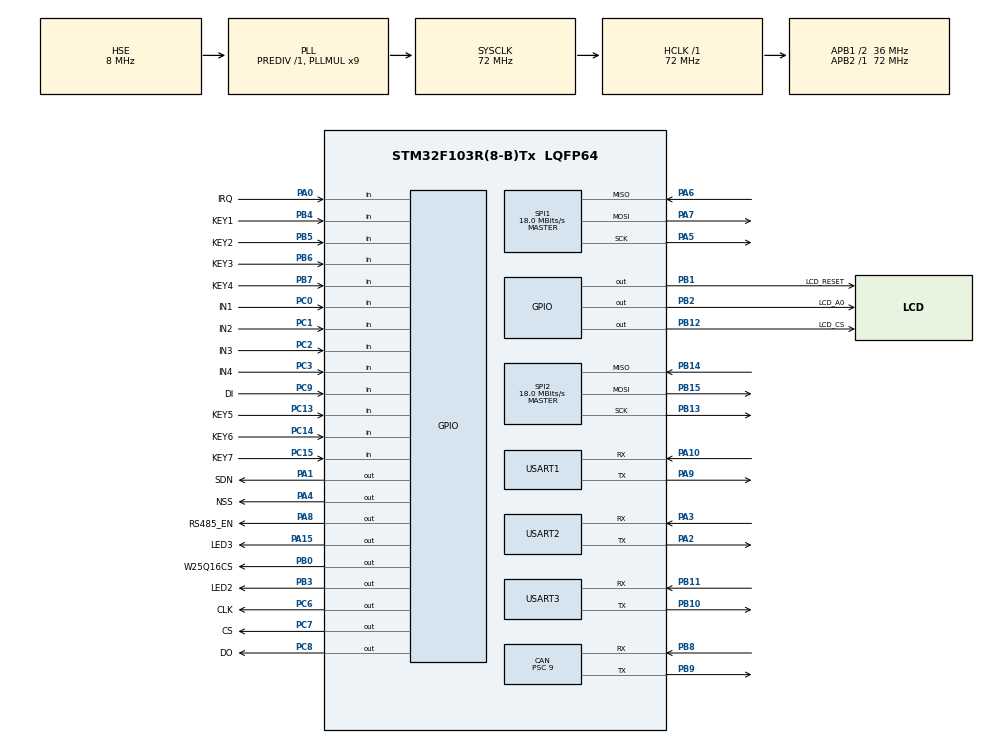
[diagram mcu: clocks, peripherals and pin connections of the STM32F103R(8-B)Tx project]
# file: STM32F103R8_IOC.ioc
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CAN.BS1=CAN_BS1_3TQ
CAN.BS2=CAN_BS2_4TQ
CAN.CalculateTimeBit=2000
CAN.CalculateTimeQuantum=250.0
CAN.NART=ENABLE
CAN.Prescaler=9
Dma.Request0=USART1_RX
Dma.Request1=USART1_TX
Dma.Request2=USART2_RX
Dma.Request3=USART2_TX
Dma.Request4=USART3_RX
Dma.Request5=USART3_TX
Dma.USART1_RX.0.Direction=DMA_PERIPH_TO_MEMORY
Dma.USART1_RX.0.Instance=DMA1_Channel5
Dma.USART1_RX.0.MemDataAlignment=DMA_MDATAALIGN_BYTE
Dma.USART1_RX.0.MemInc=DMA_MINC_ENABLE
Dma.USART1_RX.0.Mode=DMA_CIRCULAR
Dma.USART1_RX.0.PeriphDataAlignment=DMA_PDATAALIGN_BYTE
Dma.USART1_RX.0.PeriphInc=DMA_PINC_DISABLE
Dma.USART1_RX.0.Priority=DMA_PRIORITY_LOW
Dma.USART1_TX.1.Direction=DMA_MEMORY_TO_PERIPH
Dma.USART1_TX.1.Instance=DMA1_Channel4
Dma.USART1_TX.1.MemDataAlignment=DMA_MDATAALIGN_BYTE
Dma.USART1_TX.1.MemInc=DMA_MINC_ENABLE
Dma.USART1_TX.1.Mode=DMA_NORMAL
Dma.USART1_TX.1.PeriphDataAlignment=DMA_PDATAALIGN_BYTE
Dma.USART1_TX.1.PeriphInc=DMA_PINC_DISABLE
Dma.USART1_TX.1.Priority=DMA_PRIORITY_LOW
Dma.USART2_RX.2.Direction=DMA_PERIPH_TO_MEMORY
Dma.USART2_RX.2.Instance=DMA1_Channel6
Dma.USART2_RX.2.MemDataAlignment=DMA_MDATAALIGN_BYTE
Dma.USART2_RX.2.MemInc=DMA_MINC_ENABLE
Dma.USART2_RX.2.Mode=DMA_CIRCULAR
Dma.USART2_RX.2.PeriphDataAlignment=DMA_PDATAALIGN_BYTE
Dma.USART2_RX.2.PeriphInc=DMA_PINC_DISABLE
Dma.USART2_RX.2.Priority=DMA_PRIORITY_LOW
Dma.USART2_TX.3.Direction=DMA_MEMORY_TO_PERIPH
Dma.USART2_TX.3.Instance=DMA1_Channel7
Dma.USART2_TX.3.MemDataAlignment=DMA_MDATAALIGN_BYTE
Dma.USART2_TX.3.MemInc=DMA_MINC_ENABLE
Dma.USART2_TX.3.Mode=DMA_NORMAL
Dma.USART2_TX.3.PeriphDataAlignment=DMA_PDATAALIGN_BYTE
Dma.USART2_TX.3.PeriphInc=DMA_PINC_DISABLE
Dma.USART2_TX.3.Priority=DMA_PRIORITY_LOW
Dma.USART3_RX.4.Direction=DMA_PERIPH_TO_MEMORY
Dma.USART3_RX.4.Instance=DMA1_Channel3
Dma.USART3_RX.4.MemDataAlignment=DMA_MDATAALIGN_BYTE
Dma.USART3_RX.4.MemInc=DMA_MINC_ENABLE
Dma.USART3_RX.4.Mode=DMA_CIRCULAR
Dma.USART3_RX.4.PeriphDataAlignment=DMA_PDATAALIGN_BYTE
Dma.USART3_RX.4.PeriphInc=DMA_PINC_DISABLE
Dma.USART3_RX.4.Priority=DMA_PRIORITY_LOW
Dma.USART3_TX.5.Direction=DMA_MEMORY_TO_PERIPH
Dma.USART3_TX.5.Instance=DMA1_Channel2
Dma.USART3_TX.5.MemDataAlignment=DMA_MDATAALIGN_BYTE
Dma.USART3_TX.5.MemInc=DMA_MINC_ENABLE
Dma.USART3_TX.5.Mode=DMA_NORMAL
Dma.USART3_TX.5.PeriphDataAlignment=DMA_PDATAALIGN_BYTE
Dma.USART3_TX.5.PeriphInc=DMA_PINC_DISABLE
Dma.USART3_TX.5.Priority=DMA_PRIORITY_LOW
Mcu.Family=STM32F1
Mcu.Name=STM32F103R(8-B)Tx
Mcu.Package=LQFP64
NVIC.DMA1_Channel2_IRQn=true\:0\:0\:false\:false\:true\:false\:true
NVIC.DMA1_Channel3_IRQn=true\:0\:0\:false\:false\:true\:false\:true
NVIC.DMA1_Channel4_IRQn=true\:0\:0\:false\:false\:true\:false\:true
NVIC.DMA1_Channel5_IRQn=true\:0\:0\:false\:false\:true\:false\:true
NVIC.DMA1_Channel6_IRQn=true\:0\:0\:false\:false\:true\:false\:true
NVIC.DMA1_Channel7_IRQn=true\:0\:0\:false\:false\:true\:false\:true
NVIC.PriorityGroup=NVIC_PRIORITYGROUP_4
NVIC.TIM2_IRQn=true\:0\:0\:false\:false\:true\:true\:true
NVIC.TIM3_IRQn=true\:0\:0\:false\:false\:true\:true\:true
NVIC.USART1_IRQn=true\:0\:0\:false\:false\:true\:true\:true
NVIC.USART2_IRQn=true\:0\:0\:false\:false\:true\:true\:true
NVIC.USART3_IRQn=true\:0\:0\:false\:false\:true\:true\:true
NVIC.USB_LP_CAN1_RX0_IRQn=true\:0\:0\:false\:false\:true\:true\:true
PA0-WKUP.GPIO_Label=IRQ
PA0-WKUP.GPIO_PuPd=GPIO_PULLUP
PA0-WKUP.Signal=GPIO_Input
PA1.GPIO_Label=SDN
PA1.GPIO_PuPd=GPIO_PULLUP
PA1.Signal=GPIO_Output
PA10.Mode=Asynchronous
PA10.Signal=USART1_RX
PA13.Mode=Serial_Wire
PA13.Signal=SYS_JTMS-SWDIO
PA14.Mode=Serial_Wire
PA14.Signal=SYS_JTCK-SWCLK
PA15.GPIO_Label=LED3
PA15.GPIO_PuPd=GPIO_PULLUP
PA15.PinState=GPIO_PIN_SET
PA15.Signal=GPIO_Output
PA2.Mode=Asynchronous
PA2.Signal=USART2_TX
PA3.Mode=Asynchronous
PA3.Signal=USART2_RX
PA4.GPIO_Label=NSS
PA4.Signal=GPIO_Output
PA5.Mode=Full_Duplex_Master
PA5.Signal=SPI1_SCK
PA6.Mode=Full_Duplex_Master
PA6.Signal=SPI1_MISO
PA7.Mode=Full_Duplex_Master
PA7.Signal=SPI1_MOSI
PA8.GPIO_Label=RS485_EN
PA8.Signal=GPIO_Output
PA9.Mode=Asynchronous
PA9.Signal=USART1_TX
PB0.GPIO_Label=W25Q16CS
PB0.GPIO_PuPd=GPIO_PULLUP
PB0.Signal=GPIO_Output
PB1.GPIO_Label=LCD_RESET
PB1.GPIO_PuPd=GPIO_PULLUP
PB1.Signal=GPIO_Output
PB10.Mode=Asynchronous
PB10.Signal=USART3_TX
PB11.Mode=Asynchronous
PB11.Signal=USART3_RX
PB12.GPIO_Label=LCD_CS
PB12.GPIO_PuPd=GPIO_PULLUP
PB12.Signal=GPIO_Output
PB13.Mode=Full_Duplex_Master
PB13.Signal=SPI2_SCK
PB14.Mode=Full_Duplex_Master
PB14.Signal=SPI2_MISO
PB15.Mode=Full_Duplex_Master
PB15.Signal=SPI2_MOSI
PB2.GPIO_Label=LCD_A0
PB2.GPIO_PuPd=GPIO_PULLUP
PB2.Signal=GPIO_Output
PB3.GPIO_Label=LED2
PB3.GPIO_PuPd=GPIO_PULLUP
PB3.Signal=GPIO_Output
PB4.GPIO_Label=KEY1
PB4.GPIO_PuPd=GPIO_PULLUP
PB4.Signal=GPIO_Input
PB5.GPIO_Label=KEY2
PB5.GPIO_PuPd=GPIO_PULLUP
PB5.Signal=GPIO_Input
PB6.GPIO_Label=KEY3
PB6.GPIO_PuPd=GPIO_PULLUP
PB6.Signal=GPIO_Input
PB7.GPIO_Label=KEY4
PB7.GPIO_PuPd=GPIO_PULLUP
PB7.Signal=GPIO_Input
PB8.Mode=Master
PB8.Signal=CAN_RX
PB9.Mode=Master
PB9.Signal=CAN_TX
PC0.GPIO_Label=IN1
PC0.Signal=GPIO_Input
PC1.GPIO_Label=IN2
PC1.Signal=GPIO_Input
PC13-TAMPER-RTC.GPIO_Label=KEY5
PC13-TAMPER-RTC.GPIO_PuPd=GPIO_PULLUP
PC13-TAMPER-RTC.Signal=GPIO_Input
PC14-OSC32_IN.GPIO_Label=KEY6
PC14-OSC32_IN.GPIO_PuPd=GPIO_PULLUP
PC14-OSC32_IN.Signal=GPIO_Input
PC15-OSC32_OUT.GPIO_Label=KEY7
PC15-OSC32_OUT.GPIO_PuPd=GPIO_PULLUP
PC15-OSC32_OUT.Signal=GPIO_Input
PC2.GPIO_Label=IN3
PC2.Signal=GPIO_Input
PC3.GPIO_Label=IN4
PC3.Signal=GPIO_Input
PC6.GPIO_Label=CLK
PC6.PinState=GPIO_PIN_SET
PC6.Signal=GPIO_Output
PC7.GPIO_Label=CS
PC7.PinState=GPIO_PIN_SET
PC7.Signal=GPIO_Output
PC8.GPIO_Label=DO
PC8.Signal=GPIO_Output
PC9.GPIO_Label=DI
PC9.Signal=GPIO_Input
PD0-OSC_IN.Mode=HSE-External-Oscillator
PD0-OSC_IN.Signal=RCC_OSC_IN
PD1-OSC_OUT.Mode=HSE-External-Oscillator
PD1-OSC_OUT.Signal=RCC_OSC_OUT
ProjectManager.HeapSize=0x200
ProjectManager.StackSize=0x400
ProjectManager.TargetToolchain=MDK-ARM V5.27
RCC.AHBFreq_Value=72000000
RCC.APB1CLKDivider=RCC_HCLK_DIV2
RCC.APB1Freq_Value=36000000
RCC.APB1TimFreq_Value=72000000
RCC.APB2Freq_Value=72000000
RCC.APB2TimFreq_Value=72000000
RCC.HCLKFreq_Value=72000000
RCC.PLLMUL=RCC_PLL_MUL9
RCC.PLLSourceVirtual=RCC_PLLSOURCE_HSE
RCC.SYSCLKFreq_VALUE=72000000
RCC.SYSCLKSource=RCC_SYSCLKSOURCE_PLLCLK
RCC.USBFreq_Value=72000000
SPI1.BaudRatePrescaler=SPI_BAUDRATEPRESCALER_4
SPI1.CalculateBaudRate=18.0 MBits/s
SPI1.Direction=SPI_DIRECTION_2LINES
SPI1.Mode=SPI_MODE_MASTER
SPI1.VirtualType=VM_MASTER
SPI2.CalculateBaudRate=18.0 MBits/s
SPI2.Direction=SPI_DIRECTION_2LINES
SPI2.Mode=SPI_MODE_MASTER
SPI2.VirtualType=VM_MASTER
TIM2.Period=999
TIM2.Prescaler=71
TIM3.Period=999
TIM3.Prescaler=71
USART1.VirtualMode=VM_ASYNC
USART2.VirtualMode=VM_ASYNC
USART3.VirtualMode=VM_ASYNC
VP_TIM2_VS_ClockSourceINT.Mode=Internal
VP_TIM3_VS_ClockSourceINT.Mode=Internal
board=custom

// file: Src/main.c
/* USER CODE BEGIN Header */
/**
  ******************************************************************************
  * @file           : main.c
  * @brief          : Main program body
  ******************************************************************************
  * @attention
  *
  * <h2><center>&copy; Copyright (c) 2020 STMicroelectronics.
  * All rights reserved.</center></h2>
  *
  * This software component is licensed by ST under BSD 3-Clause license,
  * the "License"; You may not use this file except in compliance with the
  * License. You may obtain a copy of the License at:
  *                        opensource.org/licenses/BSD-3-Clause
  *
  ******************************************************************************
  */
/* USER CODE END Header */

#include "main.h"
#include "can.h"
#include "dma.h"
#include "spi.h"
#include "tim.h"
#include "usart.h"
#include "gpio.h"

/* USER CODE BEGIN Includes */
#include "app.h"
/* USER CODE END Includes */

void SystemClock_Config(void);

int main(void)
{

  /* MCU Configuration--------------------------------------------------------*/

  /* Reset of all peripherals, Initializes the Flash interface and the Systick. */
  HAL_Init();

  /* Configure the system clock */
  SystemClock_Config();

  /* Initialize all configured peripherals */
  MX_GPIO_Init();
  MX_DMA_Init();
  MX_CAN_Init();
  MX_SPI1_Init();
  MX_SPI2_Init();
  MX_TIM2_Init();
  MX_TIM3_Init();
  MX_USART1_UART_Init();
  MX_USART2_UART_Init();
  MX_USART3_UART_Init();

  /* Infinite loop */
  /* USER CODE BEGIN WHILE */
  while (1)
  {
	  ApplicationProgram_main();
    /* USER CODE END WHILE */

  }
}

void SystemClock_Config(void)
{
  RCC_OscInitTypeDef RCC_OscInitStruct = {0};
  RCC_ClkInitTypeDef RCC_ClkInitStruct = {0};

  /** Initializes the CPU, AHB and APB busses clocks
  */
  RCC_OscInitStruct.OscillatorType = RCC_OSCILLATORTYPE_HSE;
  RCC_OscInitStruct.HSEState = RCC_HSE_ON;
  RCC_OscInitStruct.HSEPredivValue = RCC_HSE_PREDIV_DIV1;
  RCC_OscInitStruct.HSIState = RCC_HSI_ON;
  RCC_OscInitStruct.PLL.PLLState = RCC_PLL_ON;
  RCC_OscInitStruct.PLL.PLLSource = RCC_PLLSOURCE_HSE;
  RCC_OscInitStruct.PLL.PLLMUL = RCC_PLL_MUL9;
  if (HAL_RCC_OscConfig(&RCC_OscInitStruct) != HAL_OK)
  {
    Error_Handler();
  }
  /** Initializes the CPU, AHB and APB busses clocks
  */
  RCC_ClkInitStruct.ClockType = RCC_CLOCKTYPE_HCLK|RCC_CLOCKTYPE_SYSCLK
                              |RCC_CLOCKTYPE_PCLK1|RCC_CLOCKTYPE_PCLK2;
  RCC_ClkInitStruct.SYSCLKSource = RCC_SYSCLKSOURCE_PLLCLK;
  RCC_ClkInitStruct.AHBCLKDivider = RCC_SYSCLK_DIV1;
  RCC_ClkInitStruct.APB1CLKDivider = RCC_HCLK_DIV2;
  RCC_ClkInitStruct.APB2CLKDivider = RCC_HCLK_DIV1;

  if (HAL_RCC_ClockConfig(&RCC_ClkInitStruct, FLASH_LATENCY_2) != HAL_OK)
  {
    Error_Handler();
  }
}

void Error_Handler(void)
{
}

/************************ (C) COPYRIGHT STMicroelectronics *****END OF FILE****/
